VERSION ""

NS_ :

BS_:

BU_: AMS VCU

BO_ 3221225472 VECTOR__INDEPENDENT_SIG_MSG: 0 Vector__XXX
 SG_ NewSignal_0003 : 24|8@1+ (1,0) [0|0] "" Vector__XXX
 SG_ NewSignal_0008 : 40|8@1+ (1,0) [0|0] "" Vector__XXX

BO_ 131 Start_PreCharge: 1 VCU
 SG_ Precharge_Request : 0|1@0+ (1,0) [0|0] "ON/OFF" Vector__XXX

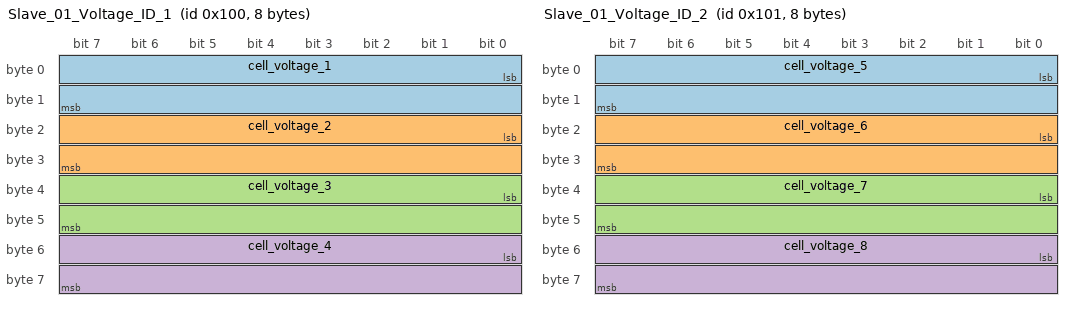
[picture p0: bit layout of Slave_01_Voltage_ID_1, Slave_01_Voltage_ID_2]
BO_ 256 Slave_01_Voltage_ID_1: 8 AMS
 SG_ cell_voltage_1 : 0|16@1+ (0.001,0) [0|0] "V" Vector__XXX
 SG_ cell_voltage_2 : 16|16@1+ (0.001,0) [0|0] "V" Vector__XXX
 SG_ cell_voltage_3 : 32|16@1+ (0.001,0) [0|0] "V" Vector__XXX
 SG_ cell_voltage_4 : 48|16@1+ (0.001,0) [0|0] "V" Vector__XXX

BO_ 257 Slave_01_Voltage_ID_2: 8 AMS
 SG_ cell_voltage_5 : 0|16@1+ (0.001,0) [0|0] "V" Vector__XXX
 SG_ cell_voltage_6 : 16|16@1+ (0.001,0) [0|0] "V" Vector__XXX
 SG_ cell_voltage_7 : 32|16@1+ (0.001,0) [0|0] "V" Vector__XXX
 SG_ cell_voltage_8 : 48|16@1+ (0.001,0) [0|0] "V" Vector__XXX

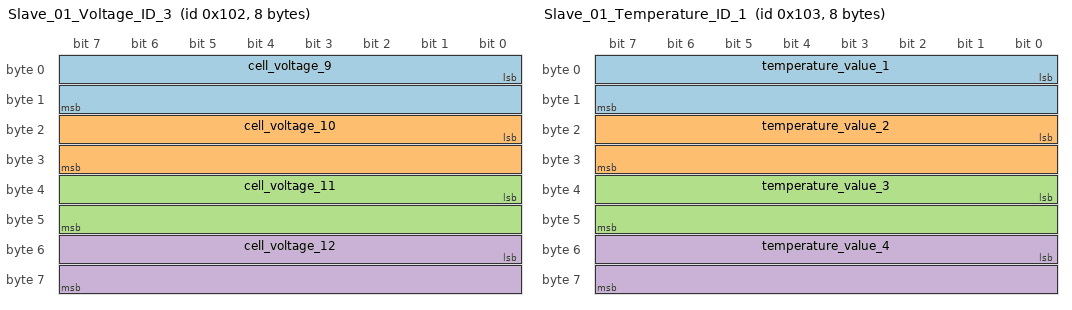
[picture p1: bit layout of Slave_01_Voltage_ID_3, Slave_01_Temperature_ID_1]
BO_ 258 Slave_01_Voltage_ID_3: 8 AMS
 SG_ cell_voltage_9 : 0|16@1+ (0.001,0) [0|0] "V" Vector__XXX
 SG_ cell_voltage_10 : 16|16@1+ (0.001,0) [0|0] "V" Vector__XXX
 SG_ cell_voltage_11 : 32|16@1+ (0.001,0) [0|0] "V" Vector__XXX
 SG_ cell_voltage_12 : 48|16@1+ (0.001,0) [0|0] "V" Vector__XXX

BO_ 259 Slave_01_Temperature_ID_1: 8 AMS
 SG_ temperature_value_1 : 0|16@1+ (0.01,0) [0|0] "ºC" Vector__XXX
 SG_ temperature_value_2 : 16|16@1+ (0.01,0) [0|0] "ºC" Vector__XXX
 SG_ temperature_value_3 : 32|16@1+ (0.01,0) [0|0] "ºC" Vector__XXX
 SG_ temperature_value_4 : 48|16@1+ (0.01,0) [0|0] "ºC" Vector__XXX

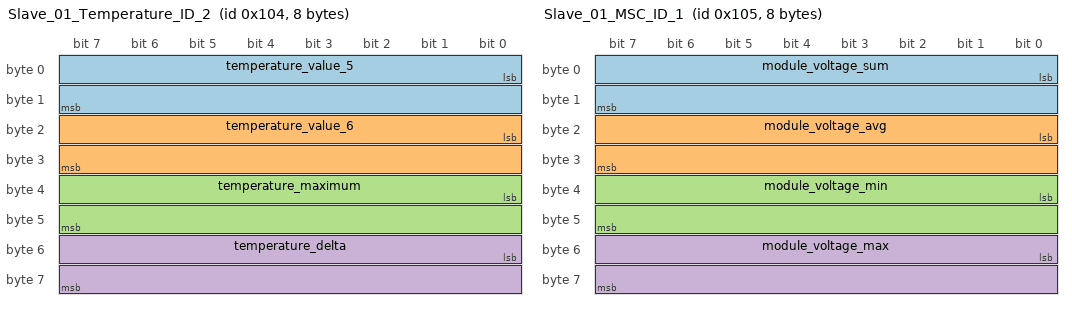
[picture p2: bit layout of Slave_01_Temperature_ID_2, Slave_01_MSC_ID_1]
BO_ 260 Slave_01_Temperature_ID_2: 8 AMS
 SG_ temperature_value_5 : 0|16@1+ (0.01,0) [0|0] "ºC" Vector__XXX
 SG_ temperature_value_6 : 16|16@1+ (0.01,0) [0|0] "ºC" Vector__XXX
 SG_ temperature_maximum : 32|16@1+ (0.01,0) [0|0] "ºC" Vector__XXX
 SG_ temperature_delta : 48|16@1+ (0.01,0) [0|0] "ºC" Vector__XXX

BO_ 261 Slave_01_MSC_ID_1: 8 AMS
 SG_ module_voltage_sum : 0|16@1+ (0.001,0) [0|0] "V" Vector__XXX
 SG_ module_voltage_avg : 16|16@1+ (0.001,0) [0|0] "V" Vector__XXX
 SG_ module_voltage_min : 32|16@1+ (0.001,0) [0|0] "V" Vector__XXX
 SG_ module_voltage_max : 48|16@1+ (0.001,0) [0|0] "V" Vector__XXX

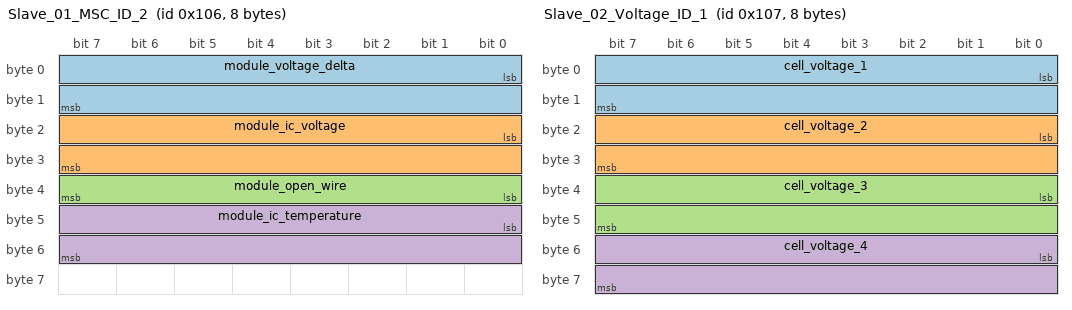
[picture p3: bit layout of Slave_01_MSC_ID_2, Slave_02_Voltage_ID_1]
BO_ 262 Slave_01_MSC_ID_2: 8 AMS
 SG_ module_voltage_delta : 0|16@1+ (0.001,0) [0|0] "V" Vector__XXX
 SG_ module_ic_voltage : 16|16@1+ (0.001,0) [0|0] "V" Vector__XXX
 SG_ module_open_wire : 32|8@1+ (1,0) [0|1] "" Vector__XXX
 SG_ module_ic_temperature : 40|16@1+ (1,0) [0|0] "ºC" Vector__XXX

BO_ 263 Slave_02_Voltage_ID_1: 8 AMS
 SG_ cell_voltage_1 : 0|16@1+ (0.001,0) [0|0] "V" Vector__XXX
 SG_ cell_voltage_2 : 16|16@1+ (0.001,0) [0|0] "V" Vector__XXX
 SG_ cell_voltage_3 : 32|16@1+ (0.001,0) [0|0] "V" Vector__XXX
 SG_ cell_voltage_4 : 48|16@1+ (0.001,0) [0|0] "V" Vector__XXX

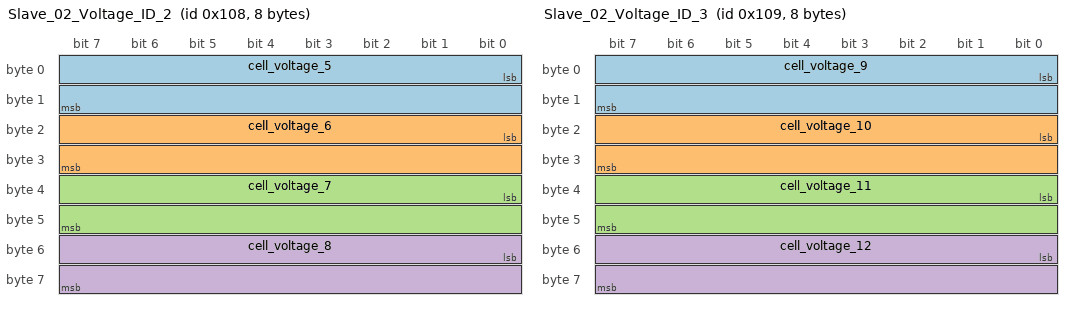
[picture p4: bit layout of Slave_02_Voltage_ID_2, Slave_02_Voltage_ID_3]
BO_ 264 Slave_02_Voltage_ID_2: 8 AMS
 SG_ cell_voltage_5 : 0|16@1+ (0.001,0) [0|0] "V" Vector__XXX
 SG_ cell_voltage_6 : 16|16@1+ (0.001,0) [0|0] "V" Vector__XXX
 SG_ cell_voltage_7 : 32|16@1+ (0.001,0) [0|0] "V" Vector__XXX
 SG_ cell_voltage_8 : 48|16@1+ (0.001,0) [0|0] "V" Vector__XXX

BO_ 265 Slave_02_Voltage_ID_3: 8 AMS
 SG_ cell_voltage_9 : 0|16@1+ (0.001,0) [0|0] "V" Vector__XXX
 SG_ cell_voltage_10 : 16|16@1+ (0.001,0) [0|0] "V" Vector__XXX
 SG_ cell_voltage_11 : 32|16@1+ (0.001,0) [0|0] "V" Vector__XXX
 SG_ cell_voltage_12 : 48|16@1+ (0.001,0) [0|0] "V" Vector__XXX

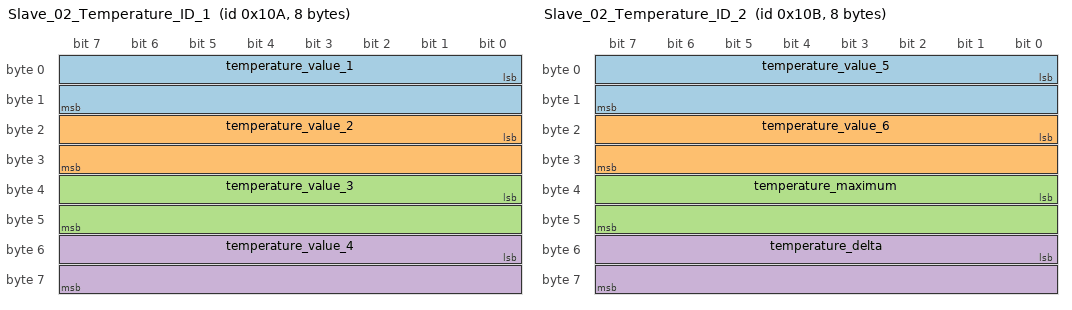
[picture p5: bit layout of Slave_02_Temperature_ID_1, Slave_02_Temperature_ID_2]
BO_ 266 Slave_02_Temperature_ID_1: 8 AMS
 SG_ temperature_value_1 : 0|16@1+ (0.01,0) [0|0] "ºC" Vector__XXX
 SG_ temperature_value_2 : 16|16@1+ (0.01,0) [0|0] "ºC" Vector__XXX
 SG_ temperature_value_3 : 32|16@1+ (0.01,0) [0|0] "ºC" Vector__XXX
 SG_ temperature_value_4 : 48|16@1+ (0.01,0) [0|0] "ºC" Vector__XXX

BO_ 267 Slave_02_Temperature_ID_2: 8 AMS
 SG_ temperature_value_5 : 0|16@1+ (0.01,0) [0|0] "ºC" Vector__XXX
 SG_ temperature_value_6 : 16|16@1+ (0.01,0) [0|0] "ºC" Vector__XXX
 SG_ temperature_maximum : 32|16@1+ (0.01,0) [0|0] "ºC" Vector__XXX
 SG_ temperature_delta : 48|16@1+ (0.01,0) [0|0] "ºC" Vector__XXX

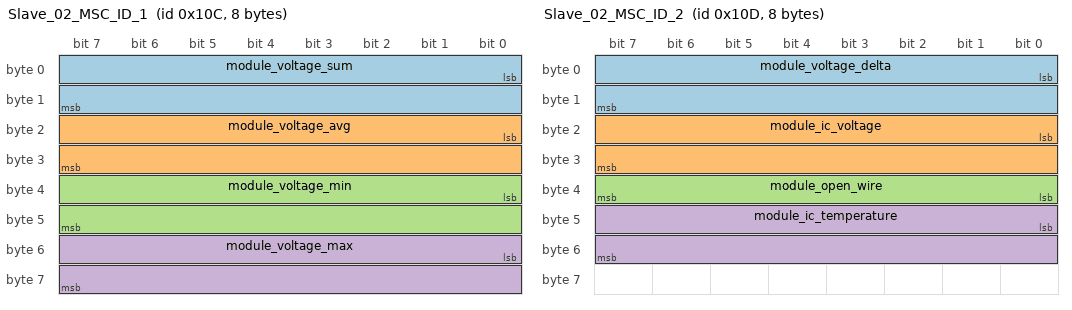
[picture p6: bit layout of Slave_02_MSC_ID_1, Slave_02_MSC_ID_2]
BO_ 268 Slave_02_MSC_ID_1: 8 AMS
 SG_ module_voltage_sum : 0|16@1+ (0.001,0) [0|0] "V" Vector__XXX
 SG_ module_voltage_avg : 16|16@1+ (0.001,0) [0|0] "V" Vector__XXX
 SG_ module_voltage_min : 32|16@1+ (0.001,0) [0|0] "V" Vector__XXX
 SG_ module_voltage_max : 48|16@1+ (0.001,0) [0|0] "V" Vector__XXX

BO_ 269 Slave_02_MSC_ID_2: 8 AMS
 SG_ module_voltage_delta : 0|16@1+ (0.001,0) [0|0] "V" Vector__XXX
 SG_ module_ic_voltage : 16|16@1+ (0.001,0) [0|0] "V" Vector__XXX
 SG_ module_open_wire : 32|8@1+ (1,0) [0|1] "" Vector__XXX
 SG_ module_ic_temperature : 40|16@1+ (1,0) [0|0] "ºC" Vector__XXX

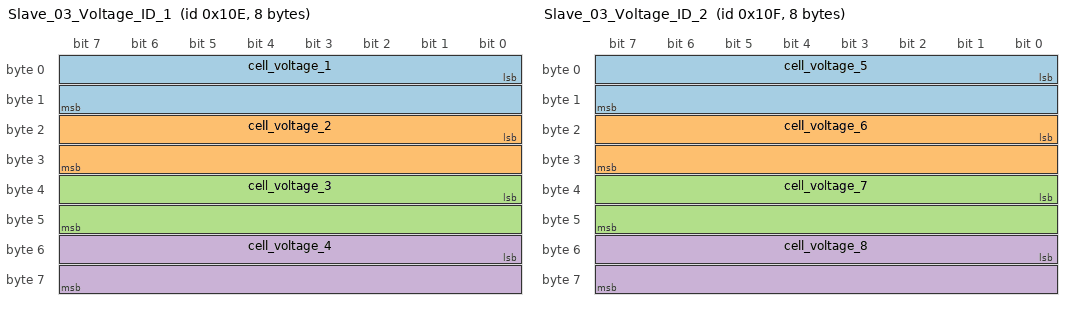
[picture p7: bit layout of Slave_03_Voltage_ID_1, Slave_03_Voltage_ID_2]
BO_ 270 Slave_03_Voltage_ID_1: 8 AMS
 SG_ cell_voltage_1 : 0|16@1+ (0.001,0) [0|0] "V" Vector__XXX
 SG_ cell_voltage_2 : 16|16@1+ (0.001,0) [0|0] "V" Vector__XXX
 SG_ cell_voltage_3 : 32|16@1+ (0.001,0) [0|0] "V" Vector__XXX
 SG_ cell_voltage_4 : 48|16@1+ (0.001,0) [0|0] "V" Vector__XXX

BO_ 271 Slave_03_Voltage_ID_2: 8 AMS
 SG_ cell_voltage_5 : 0|16@1+ (0.001,0) [0|0] "V" Vector__XXX
 SG_ cell_voltage_6 : 16|16@1+ (0.001,0) [0|0] "V" Vector__XXX
 SG_ cell_voltage_7 : 32|16@1+ (0.001,0) [0|0] "V" Vector__XXX
 SG_ cell_voltage_8 : 48|16@1+ (0.001,0) [0|0] "V" Vector__XXX

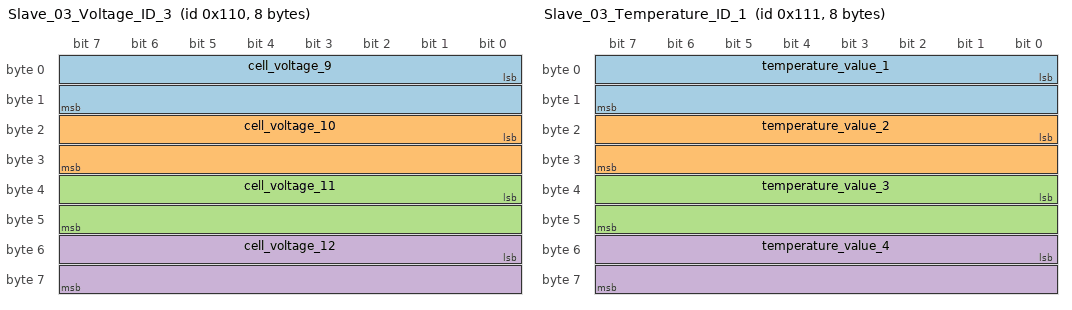
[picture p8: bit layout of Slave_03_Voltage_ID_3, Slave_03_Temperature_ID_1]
BO_ 272 Slave_03_Voltage_ID_3: 8 AMS
 SG_ cell_voltage_9 : 0|16@1+ (0.001,0) [0|0] "V" Vector__XXX
 SG_ cell_voltage_10 : 16|16@1+ (0.001,0) [0|0] "V" Vector__XXX
 SG_ cell_voltage_11 : 32|16@1+ (0.001,0) [0|0] "V" Vector__XXX
 SG_ cell_voltage_12 : 48|16@1+ (0.001,0) [0|0] "V" Vector__XXX

BO_ 273 Slave_03_Temperature_ID_1: 8 AMS
 SG_ temperature_value_1 : 0|16@1+ (0.01,0) [0|0] "ºC" Vector__XXX
 SG_ temperature_value_2 : 16|16@1+ (0.01,0) [0|0] "ºC" Vector__XXX
 SG_ temperature_value_3 : 32|16@1+ (0.01,0) [0|0] "ºC" Vector__XXX
 SG_ temperature_value_4 : 48|16@1+ (0.01,0) [0|0] "ºC" Vector__XXX

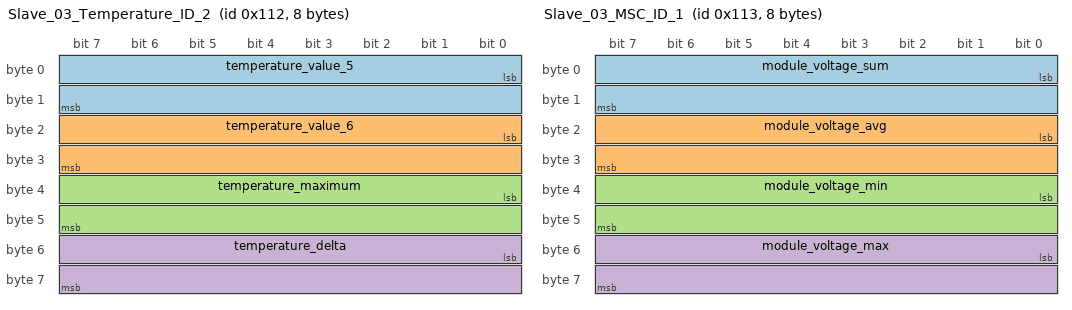
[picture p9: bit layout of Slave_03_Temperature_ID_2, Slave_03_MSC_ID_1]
BO_ 274 Slave_03_Temperature_ID_2: 8 AMS
 SG_ temperature_value_5 : 0|16@1+ (0.01,0) [0|0] "ºC" Vector__XXX
 SG_ temperature_value_6 : 16|16@1+ (0.01,0) [0|0] "ºC" Vector__XXX
 SG_ temperature_maximum : 32|16@1+ (0.01,0) [0|0] "ºC" Vector__XXX
 SG_ temperature_delta : 48|16@1+ (0.01,0) [0|0] "ºC" Vector__XXX

BO_ 275 Slave_03_MSC_ID_1: 8 AMS
 SG_ module_voltage_sum : 0|16@1+ (0.001,0) [0|0] "V" Vector__XXX
 SG_ module_voltage_avg : 16|16@1+ (0.001,0) [0|0] "V" Vector__XXX
 SG_ module_voltage_min : 32|16@1+ (0.001,0) [0|0] "V" Vector__XXX
 SG_ module_voltage_max : 48|16@1+ (0.001,0) [0|0] "V" Vector__XXX

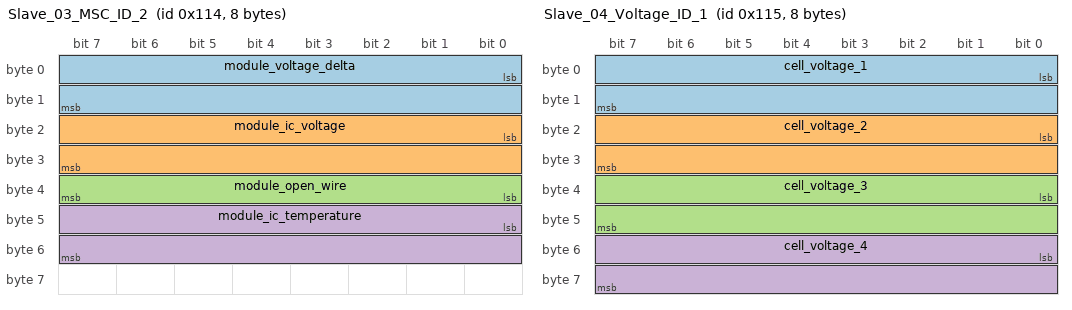
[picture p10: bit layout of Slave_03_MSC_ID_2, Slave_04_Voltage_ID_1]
BO_ 276 Slave_03_MSC_ID_2: 8 AMS
 SG_ module_voltage_delta : 0|16@1+ (0.001,0) [0|0] "V" Vector__XXX
 SG_ module_ic_voltage : 16|16@1+ (0.001,0) [0|0] "V" Vector__XXX
 SG_ module_open_wire : 32|8@1+ (1,0) [0|1] "" Vector__XXX
 SG_ module_ic_temperature : 40|16@1+ (1,0) [0|0] "ºC" Vector__XXX

BO_ 277 Slave_04_Voltage_ID_1: 8 AMS
 SG_ cell_voltage_1 : 0|16@1+ (0.001,0) [0|0] "V" Vector__XXX
 SG_ cell_voltage_2 : 16|16@1+ (0.001,0) [0|0] "V" Vector__XXX
 SG_ cell_voltage_3 : 32|16@1+ (0.001,0) [0|0] "V" Vector__XXX
 SG_ cell_voltage_4 : 48|16@1+ (0.001,0) [0|0] "V" Vector__XXX

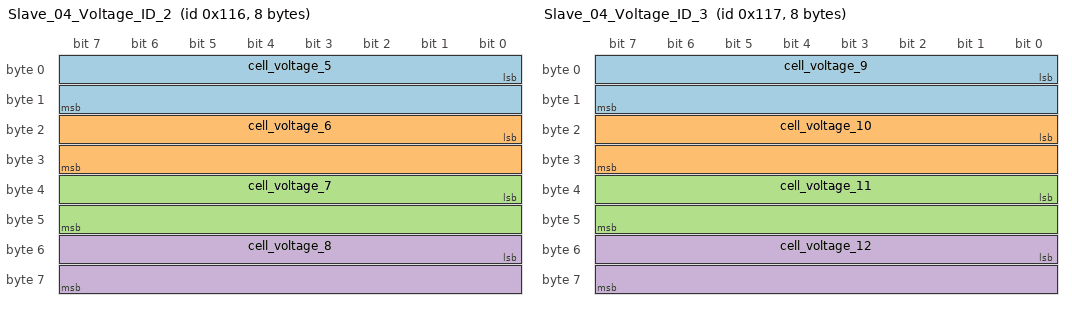
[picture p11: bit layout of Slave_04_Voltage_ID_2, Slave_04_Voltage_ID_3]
BO_ 278 Slave_04_Voltage_ID_2: 8 AMS
 SG_ cell_voltage_5 : 0|16@1+ (0.001,0) [0|0] "V" Vector__XXX
 SG_ cell_voltage_6 : 16|16@1+ (0.001,0) [0|0] "V" Vector__XXX
 SG_ cell_voltage_7 : 32|16@1+ (0.001,0) [0|0] "V" Vector__XXX
 SG_ cell_voltage_8 : 48|16@1+ (0.001,0) [0|0] "V" Vector__XXX

BO_ 279 Slave_04_Voltage_ID_3: 8 AMS
 SG_ cell_voltage_9 : 0|16@1+ (0.001,0) [0|0] "V" Vector__XXX
 SG_ cell_voltage_10 : 16|16@1+ (0.001,0) [0|0] "V" Vector__XXX
 SG_ cell_voltage_11 : 32|16@1+ (0.001,0) [0|0] "V" Vector__XXX
 SG_ cell_voltage_12 : 48|16@1+ (0.001,0) [0|0] "V" Vector__XXX

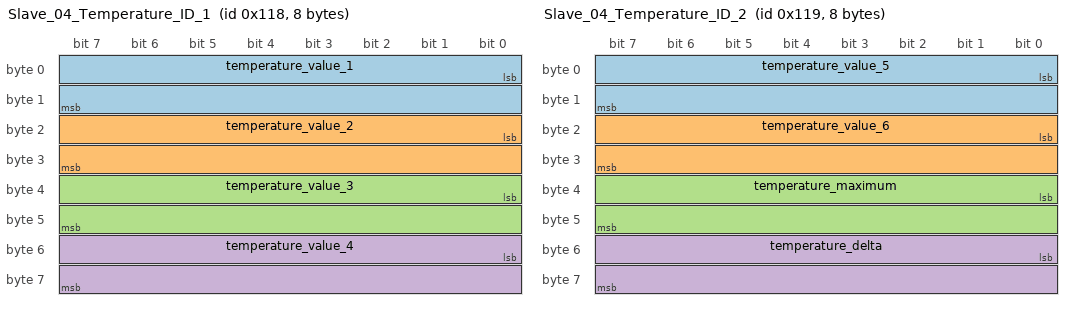
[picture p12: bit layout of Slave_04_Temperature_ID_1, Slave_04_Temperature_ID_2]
BO_ 280 Slave_04_Temperature_ID_1: 8 AMS
 SG_ temperature_value_1 : 0|16@1+ (0.01,0) [0|0] "ºC" Vector__XXX
 SG_ temperature_value_2 : 16|16@1+ (0.01,0) [0|0] "ºC" Vector__XXX
 SG_ temperature_value_3 : 32|16@1+ (0.01,0) [0|0] "ºC" Vector__XXX
 SG_ temperature_value_4 : 48|16@1+ (0.01,0) [0|0] "ºC" Vector__XXX

BO_ 281 Slave_04_Temperature_ID_2: 8 AMS
 SG_ temperature_value_5 : 0|16@1+ (0.01,0) [0|0] "ºC" Vector__XXX
 SG_ temperature_value_6 : 16|16@1+ (0.01,0) [0|0] "ºC" Vector__XXX
 SG_ temperature_maximum : 32|16@1+ (0.01,0) [0|0] "ºC" Vector__XXX
 SG_ temperature_delta : 48|16@1+ (0.01,0) [0|0] "ºC" Vector__XXX

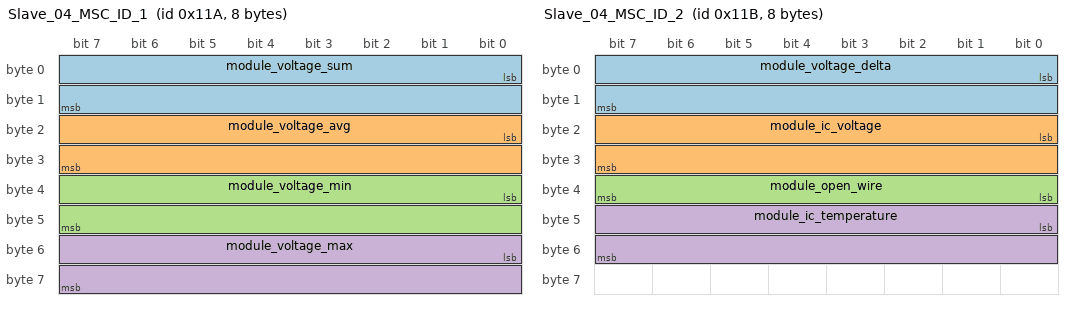
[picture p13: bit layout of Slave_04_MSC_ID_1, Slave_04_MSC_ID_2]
BO_ 282 Slave_04_MSC_ID_1: 8 AMS
 SG_ module_voltage_sum : 0|16@1+ (0.001,0) [0|0] "V" Vector__XXX
 SG_ module_voltage_avg : 16|16@1+ (0.001,0) [0|0] "V" Vector__XXX
 SG_ module_voltage_min : 32|16@1+ (0.001,0) [0|0] "V" Vector__XXX
 SG_ module_voltage_max : 48|16@1+ (0.001,0) [0|0] "V" Vector__XXX

BO_ 283 Slave_04_MSC_ID_2: 8 AMS
 SG_ module_voltage_delta : 0|16@1+ (0.001,0) [0|0] "V" Vector__XXX
 SG_ module_ic_voltage : 16|16@1+ (0.001,0) [0|0] "V" Vector__XXX
 SG_ module_open_wire : 32|8@1+ (1,0) [0|1] "" Vector__XXX
 SG_ module_ic_temperature : 40|16@1+ (1,0) [0|0] "ºC" Vector__XXX

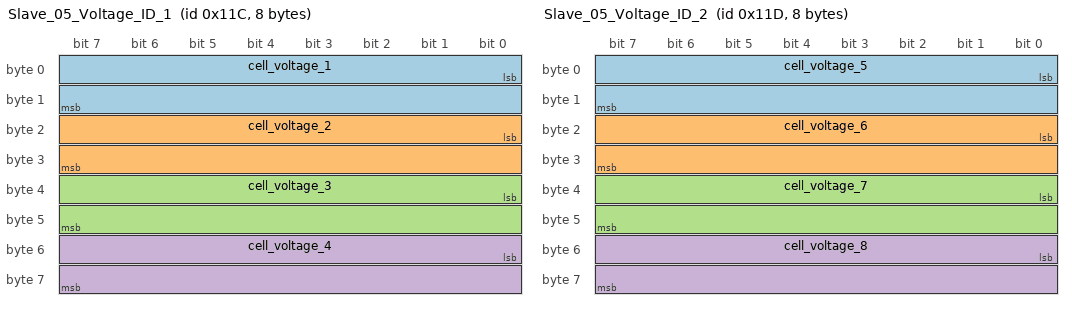
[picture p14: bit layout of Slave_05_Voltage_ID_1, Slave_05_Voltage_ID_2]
BO_ 284 Slave_05_Voltage_ID_1: 8 AMS
 SG_ cell_voltage_1 : 0|16@1+ (0.001,0) [0|0] "V" Vector__XXX
 SG_ cell_voltage_2 : 16|16@1+ (0.001,0) [0|0] "V" Vector__XXX
 SG_ cell_voltage_3 : 32|16@1+ (0.001,0) [0|0] "V" Vector__XXX
 SG_ cell_voltage_4 : 48|16@1+ (0.001,0) [0|0] "V" Vector__XXX

BO_ 285 Slave_05_Voltage_ID_2: 8 AMS
 SG_ cell_voltage_5 : 0|16@1+ (0.001,0) [0|0] "V" Vector__XXX
 SG_ cell_voltage_6 : 16|16@1+ (0.001,0) [0|0] "V" Vector__XXX
 SG_ cell_voltage_7 : 32|16@1+ (0.001,0) [0|0] "V" Vector__XXX
 SG_ cell_voltage_8 : 48|16@1+ (0.001,0) [0|0] "V" Vector__XXX

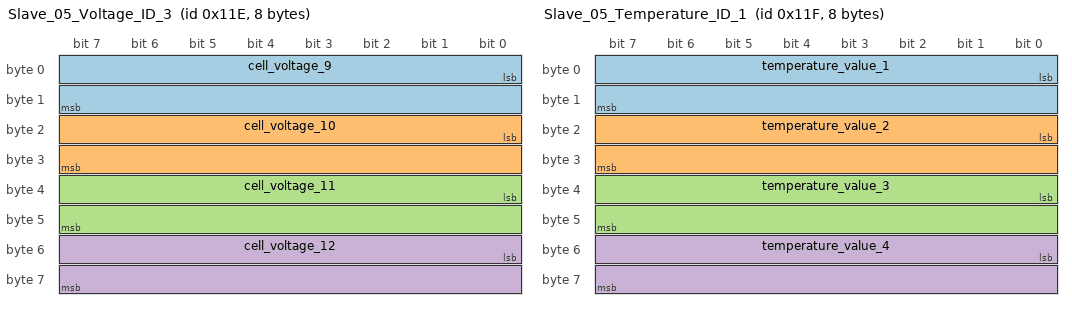
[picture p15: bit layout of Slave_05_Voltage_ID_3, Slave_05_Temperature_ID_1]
BO_ 286 Slave_05_Voltage_ID_3: 8 AMS
 SG_ cell_voltage_9 : 0|16@1+ (0.001,0) [0|0] "V" Vector__XXX
 SG_ cell_voltage_10 : 16|16@1+ (0.001,0) [0|0] "V" Vector__XXX
 SG_ cell_voltage_11 : 32|16@1+ (0.001,0) [0|0] "V" Vector__XXX
 SG_ cell_voltage_12 : 48|16@1+ (0.001,0) [0|0] "V" Vector__XXX

BO_ 287 Slave_05_Temperature_ID_1: 8 AMS
 SG_ temperature_value_1 : 0|16@1+ (0.01,0) [0|0] "ºC" Vector__XXX
 SG_ temperature_value_2 : 16|16@1+ (0.01,0) [0|0] "ºC" Vector__XXX
 SG_ temperature_value_3 : 32|16@1+ (0.01,0) [0|0] "ºC" Vector__XXX
 SG_ temperature_value_4 : 48|16@1+ (0.01,0) [0|0] "ºC" Vector__XXX

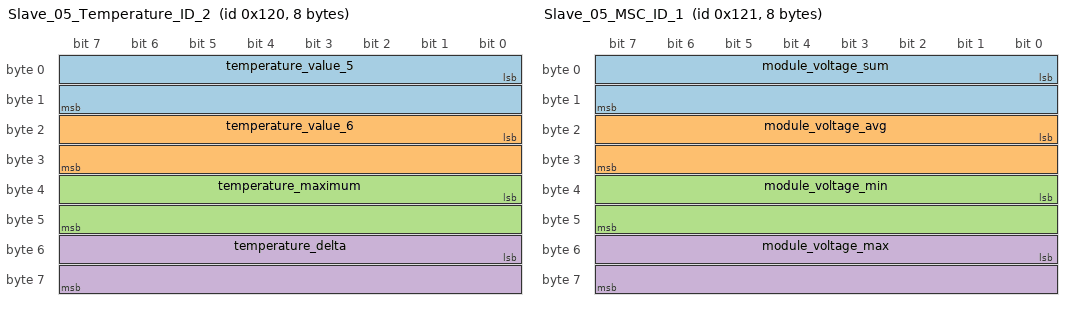
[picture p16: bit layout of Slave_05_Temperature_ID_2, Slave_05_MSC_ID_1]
BO_ 288 Slave_05_Temperature_ID_2: 8 AMS
 SG_ temperature_value_5 : 0|16@1+ (0.01,0) [0|0] "ºC" Vector__XXX
 SG_ temperature_value_6 : 16|16@1+ (0.01,0) [0|0] "ºC" Vector__XXX
 SG_ temperature_maximum : 32|16@1+ (0.01,0) [0|0] "ºC" Vector__XXX
 SG_ temperature_delta : 48|16@1+ (0.01,0) [0|0] "ºC" Vector__XXX

BO_ 289 Slave_05_MSC_ID_1: 8 AMS
 SG_ module_voltage_sum : 0|16@1+ (0.001,0) [0|0] "V" Vector__XXX
 SG_ module_voltage_avg : 16|16@1+ (0.001,0) [0|0] "V" Vector__XXX
 SG_ module_voltage_min : 32|16@1+ (0.001,0) [0|0] "V" Vector__XXX
 SG_ module_voltage_max : 48|16@1+ (0.001,0) [0|0] "V" Vector__XXX

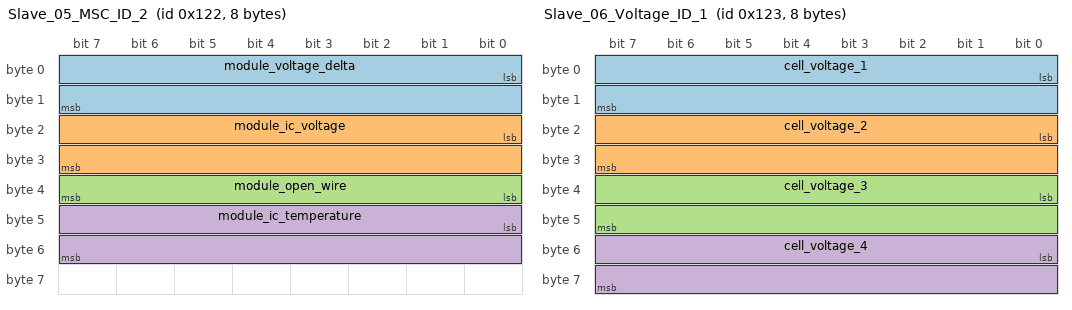
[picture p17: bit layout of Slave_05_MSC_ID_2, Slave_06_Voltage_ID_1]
BO_ 290 Slave_05_MSC_ID_2: 8 AMS
 SG_ module_voltage_delta : 0|16@1+ (0.001,0) [0|0] "V" Vector__XXX
 SG_ module_ic_voltage : 16|16@1+ (0.001,0) [0|0] "V" Vector__XXX
 SG_ module_open_wire : 32|8@1+ (1,0) [0|1] "" Vector__XXX
 SG_ module_ic_temperature : 40|16@1+ (1,0) [0|0] "ºC" Vector__XXX

BO_ 291 Slave_06_Voltage_ID_1: 8 AMS
 SG_ cell_voltage_1 : 0|16@1+ (0.001,0) [0|0] "V" Vector__XXX
 SG_ cell_voltage_2 : 16|16@1+ (0.001,0) [0|0] "V" Vector__XXX
 SG_ cell_voltage_3 : 32|16@1+ (0.001,0) [0|0] "V" Vector__XXX
 SG_ cell_voltage_4 : 48|16@1+ (0.001,0) [0|0] "V" Vector__XXX

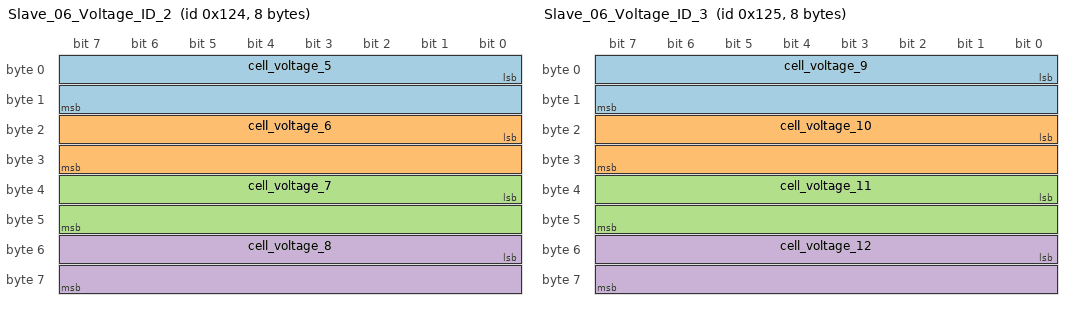
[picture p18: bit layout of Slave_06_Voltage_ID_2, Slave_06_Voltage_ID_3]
BO_ 292 Slave_06_Voltage_ID_2: 8 AMS
 SG_ cell_voltage_5 : 0|16@1+ (0.001,0) [0|0] "V" Vector__XXX
 SG_ cell_voltage_6 : 16|16@1+ (0.001,0) [0|0] "V" Vector__XXX
 SG_ cell_voltage_7 : 32|16@1+ (0.001,0) [0|0] "V" Vector__XXX
 SG_ cell_voltage_8 : 48|16@1+ (0.001,0) [0|0] "V" Vector__XXX

BO_ 293 Slave_06_Voltage_ID_3: 8 AMS
 SG_ cell_voltage_9 : 0|16@1+ (0.001,0) [0|0] "V" Vector__XXX
 SG_ cell_voltage_10 : 16|16@1+ (0.001,0) [0|0] "V" Vector__XXX
 SG_ cell_voltage_11 : 32|16@1+ (0.001,0) [0|0] "V" Vector__XXX
 SG_ cell_voltage_12 : 48|16@1+ (0.001,0) [0|0] "V" Vector__XXX

BO_ 294 Slave_06_Temperature_ID_1: 8 AMS
 SG_ temperature_value_1 : 0|16@1+ (0.01,0) [0|0] "ºC" Vector__XXX
 SG_ temperature_value_2 : 16|16@1+ (0.01,0) [0|0] "ºC" Vector__XXX
 SG_ temperature_value_3 : 32|16@1+ (0.01,0) [0|0] "ºC" Vector__XXX
 SG_ temperature_value_4 : 48|16@1+ (0.01,0) [0|0] "ºC" Vector__XXX

BO_ 295 Slave_06_Temperature_ID_2: 8 AMS
 SG_ temperature_value_5 : 0|16@1+ (0.01,0) [0|0] "ºC" Vector__XXX
 SG_ temperature_value_6 : 16|16@1+ (0.01,0) [0|0] "ºC" Vector__XXX
 SG_ temperature_maximum : 32|16@1+ (0.01,0) [0|0] "ºC" Vector__XXX
 SG_ temperature_delta : 48|16@1+ (0.01,0) [0|0] "ºC" Vector__XXX

BO_ 296 Slave_06_MSC_ID_1: 8 AMS
 SG_ module_voltage_sum : 0|16@1+ (0.001,0) [0|0] "V" Vector__XXX
 SG_ module_voltage_avg : 16|16@1+ (0.001,0) [0|0] "V" Vector__XXX
 SG_ module_voltage_min : 32|16@1+ (0.001,0) [0|0] "V" Vector__XXX
 SG_ module_voltage_max : 48|16@1+ (0.001,0) [0|0] "V" Vector__XXX

BO_ 297 Slave_06_MSC_ID_2: 8 AMS
 SG_ module_voltage_delta : 0|16@1+ (0.001,0) [0|0] "V" Vector__XXX
 SG_ module_ic_voltage : 16|16@1+ (0.001,0) [0|0] "V" Vector__XXX
 SG_ module_open_wire : 32|8@1+ (1,0) [0|1] "" Vector__XXX
 SG_ module_ic_temperature : 40|16@1+ (1,0) [0|0] "ºC" Vector__XXX

BO_ 298 Slave_07_Voltage_ID_1: 8 AMS
 SG_ cell_voltage_1 : 0|16@1+ (0.001,0) [0|0] "V" Vector__XXX
 SG_ cell_voltage_2 : 16|16@1+ (0.001,0) [0|0] "V" Vector__XXX
 SG_ cell_voltage_3 : 32|16@1+ (0.001,0) [0|0] "V" Vector__XXX
 SG_ cell_voltage_4 : 48|16@1+ (0.001,0) [0|0] "V" Vector__XXX

BO_ 299 Slave_07_Voltage_ID_2: 8 AMS
 SG_ cell_voltage_5 : 0|16@1+ (0.001,0) [0|0] "V" Vector__XXX
 SG_ cell_voltage_6 : 16|16@1+ (0.001,0) [0|0] "V" Vector__XXX
 SG_ cell_voltage_7 : 32|16@1+ (0.001,0) [0|0] "V" Vector__XXX
 SG_ cell_voltage_8 : 48|16@1+ (0.001,0) [0|0] "V" Vector__XXX

BO_ 300 Slave_07_Voltage_ID_3: 8 AMS
 SG_ cell_voltage_9 : 0|16@1+ (0.001,0) [0|0] "V" Vector__XXX
 SG_ cell_voltage_10 : 16|16@1+ (0.001,0) [0|0] "V" Vector__XXX
 SG_ cell_voltage_11 : 32|16@1+ (0.001,0) [0|0] "V" Vector__XXX
 SG_ cell_voltage_12 : 48|16@1+ (0.001,0) [0|0] "V" Vector__XXX

BO_ 301 Slave_07_Temperature_ID_1: 8 AMS
 SG_ temperature_value_1 : 0|16@1+ (0.01,0) [0|0] "ºC" Vector__XXX
 SG_ temperature_value_2 : 16|16@1+ (0.01,0) [0|0] "ºC" Vector__XXX
 SG_ temperature_value_3 : 32|16@1+ (0.01,0) [0|0] "ºC" Vector__XXX
 SG_ temperature_value_4 : 48|16@1+ (0.01,0) [0|0] "ºC" Vector__XXX

BO_ 302 Slave_07_Temperature_ID_2: 8 AMS
 SG_ temperature_value_5 : 0|16@1+ (0.01,0) [0|0] "ºC" Vector__XXX
 SG_ temperature_value_6 : 16|16@1+ (0.01,0) [0|0] "ºC" Vector__XXX
 SG_ temperature_maximum : 32|16@1+ (0.01,0) [0|0] "ºC" Vector__XXX
 SG_ temperature_delta : 48|16@1+ (0.01,0) [0|0] "ºC" Vector__XXX

BO_ 303 Slave_07_MSC_ID_1: 8 AMS
 SG_ module_voltage_sum : 0|16@1+ (0.001,0) [0|0] "V" Vector__XXX
 SG_ module_voltage_avg : 16|16@1+ (0.001,0) [0|0] "V" Vector__XXX
 SG_ module_voltage_min : 32|16@1+ (0.001,0) [0|0] "V" Vector__XXX
 SG_ module_voltage_max : 48|16@1+ (0.001,0) [0|0] "V" Vector__XXX

BO_ 304 Slave_07_MSC_ID_2: 8 AMS
 SG_ module_voltage_delta : 0|16@1+ (0.001,0) [0|0] "V" Vector__XXX
 SG_ module_ic_voltage : 16|16@1+ (0.001,0) [0|0] "V" Vector__XXX
 SG_ module_open_wire : 32|8@1+ (1,0) [0|1] "" Vector__XXX
 SG_ module_ic_temperature : 40|16@1+ (1,0) [0|0] "ºC" Vector__XXX

BO_ 305 Slave_08_Voltage_ID_1: 8 AMS
 SG_ cell_voltage_1 : 0|16@1+ (0.001,0) [0|0] "V" Vector__XXX
 SG_ cell_voltage_2 : 16|16@1+ (0.001,0) [0|0] "V" Vector__XXX
 SG_ cell_voltage_3 : 32|16@1+ (0.001,0) [0|0] "V" Vector__XXX
 SG_ cell_voltage_4 : 48|16@1+ (0.001,0) [0|0] "V" Vector__XXX

BO_ 306 Slave_08_Voltage_ID_2: 8 AMS
 SG_ cell_voltage_5 : 0|16@1+ (0.001,0) [0|0] "V" Vector__XXX
 SG_ cell_voltage_6 : 16|16@1+ (0.001,0) [0|0] "V" Vector__XXX
 SG_ cell_voltage_7 : 32|16@1+ (0.001,0) [0|0] "V" Vector__XXX
 SG_ cell_voltage_8 : 48|16@1+ (0.001,0) [0|0] "V" Vector__XXX

BO_ 307 Slave_08_Voltage_ID_3: 8 AMS
 SG_ cell_voltage_9 : 0|16@1+ (0.001,0) [0|0] "V" Vector__XXX
 SG_ cell_voltage_10 : 16|16@1+ (0.001,0) [0|0] "V" Vector__XXX
 SG_ cell_voltage_11 : 32|16@1+ (0.001,0) [0|0] "V" Vector__XXX
 SG_ cell_voltage_12 : 48|16@1+ (0.001,0) [0|0] "V" Vector__XXX

BO_ 308 Slave_08_Temperature_ID_1: 8 AMS
 SG_ temperature_value_1 : 0|16@1+ (0.01,0) [0|0] "ºC" Vector__XXX
 SG_ temperature_value_2 : 16|16@1+ (0.01,0) [0|0] "ºC" Vector__XXX
 SG_ temperature_value_3 : 32|16@1+ (0.01,0) [0|0] "ºC" Vector__XXX
 SG_ temperature_value_4 : 48|16@1+ (0.01,0) [0|0] "ºC" Vector__XXX

BO_ 309 Slave_08_Temperature_ID_2: 8 AMS
 SG_ temperature_value_5 : 0|16@1+ (0.01,0) [0|0] "ºC" Vector__XXX
 SG_ temperature_value_6 : 16|16@1+ (0.01,0) [0|0] "ºC" Vector__XXX
 SG_ temperature_maximum : 32|16@1+ (0.01,0) [0|0] "ºC" Vector__XXX
 SG_ temperature_delta : 48|16@1+ (0.01,0) [0|0] "ºC" Vector__XXX

BO_ 310 Slave_08_MSC_ID_1: 8 AMS
 SG_ module_voltage_sum : 0|16@1+ (0.001,0) [0|0] "V" Vector__XXX
 SG_ module_voltage_avg : 16|16@1+ (0.001,0) [0|0] "V" Vector__XXX
 SG_ module_voltage_min : 32|16@1+ (0.001,0) [0|0] "V" Vector__XXX
 SG_ module_voltage_max : 48|16@1+ (0.001,0) [0|0] "V" Vector__XXX

BO_ 311 Slave_08_MSC_ID_2: 8 AMS
 SG_ module_voltage_delta : 0|16@1+ (0.001,0) [0|0] "V" Vector__XXX
 SG_ module_ic_voltage : 16|16@1+ (0.001,0) [0|0] "V" Vector__XXX
 SG_ module_open_wire : 32|8@1+ (1,0) [0|1] "" Vector__XXX
 SG_ module_ic_temperature : 40|16@1+ (1,0) [0|0] "ºC" Vector__XXX

BO_ 312 Slave_09_Voltage_ID_1: 8 AMS
 SG_ cell_voltage_1 : 0|16@1+ (0.001,0) [0|0] "V" Vector__XXX
 SG_ cell_voltage_2 : 16|16@1+ (0.001,0) [0|0] "V" Vector__XXX
 SG_ cell_voltage_3 : 32|16@1+ (0.001,0) [0|0] "V" Vector__XXX
 SG_ cell_voltage_4 : 48|16@1+ (0.001,0) [0|0] "V" Vector__XXX

BO_ 313 Slave_09_Voltage_ID_2: 8 AMS
 SG_ cell_voltage_5 : 0|16@1+ (0.001,0) [0|0] "V" Vector__XXX
 SG_ cell_voltage_6 : 16|16@1+ (0.001,0) [0|0] "V" Vector__XXX
 SG_ cell_voltage_7 : 32|16@1+ (0.001,0) [0|0] "V" Vector__XXX
 SG_ cell_voltage_8 : 48|16@1+ (0.001,0) [0|0] "V" Vector__XXX

BO_ 314 Slave_09_Voltage_ID_3: 8 AMS
 SG_ cell_voltage_9 : 0|16@1+ (0.001,0) [0|0] "V" Vector__XXX
 SG_ cell_voltage_10 : 16|16@1+ (0.001,0) [0|0] "V" Vector__XXX
 SG_ cell_voltage_11 : 32|16@1+ (0.001,0) [0|0] "V" Vector__XXX
 SG_ cell_voltage_12 : 48|16@1+ (0.001,0) [0|0] "V" Vector__XXX

BO_ 315 Slave_09_Temperature_ID_1: 8 AMS
 SG_ temperature_value_1 : 0|16@1+ (0.01,0) [0|0] "ºC" Vector__XXX
 SG_ temperature_value_2 : 16|16@1+ (0.01,0) [0|0] "ºC" Vector__XXX
 SG_ temperature_value_3 : 32|16@1+ (0.01,0) [0|0] "ºC" Vector__XXX
 SG_ temperature_value_4 : 48|16@1+ (0.01,0) [0|0] "ºC" Vector__XXX

BO_ 316 Slave_09_Temperature_ID_2: 8 AMS
 SG_ temperature_value_5 : 0|16@1+ (0.01,0) [0|0] "ºC" Vector__XXX
 SG_ temperature_value_6 : 16|16@1+ (0.01,0) [0|0] "ºC" Vector__XXX
 SG_ temperature_maximum : 32|16@1+ (0.01,0) [0|0] "ºC" Vector__XXX
 SG_ temperature_delta : 48|16@1+ (0.01,0) [0|0] "ºC" Vector__XXX

BO_ 317 Slave_09_MSC_ID_1: 8 AMS
 SG_ module_voltage_sum : 0|16@1+ (0.001,0) [0|0] "V" Vector__XXX
 SG_ module_voltage_avg : 16|16@1+ (0.001,0) [0|0] "V" Vector__XXX
 SG_ module_voltage_min : 32|16@1+ (0.001,0) [0|0] "V" Vector__XXX
 SG_ module_voltage_max : 48|16@1+ (0.001,0) [0|0] "V" Vector__XXX

BO_ 318 Slave_09_MSC_ID_2: 8 AMS
 SG_ module_voltage_delta : 0|16@1+ (0.001,0) [0|0] "V" Vector__XXX
 SG_ module_ic_voltage : 16|16@1+ (0.001,0) [0|0] "V" Vector__XXX
 SG_ module_open_wire : 32|8@1+ (1,0) [0|1] "" Vector__XXX
 SG_ module_ic_temperature : 40|16@1+ (1,0) [0|0] "ºC" Vector__XXX

BO_ 319 Slave_10_Voltage_ID_1: 8 AMS
 SG_ cell_voltage_1 : 0|16@1+ (0.001,0) [0|0] "V" Vector__XXX
 SG_ cell_voltage_2 : 16|16@1+ (0.001,0) [0|0] "V" Vector__XXX
 SG_ cell_voltage_3 : 32|16@1+ (0.001,0) [0|0] "V" Vector__XXX
 SG_ cell_voltage_4 : 48|16@1+ (0.001,0) [0|0] "V" Vector__XXX

BO_ 320 Slave_10_Voltage_ID_2: 8 AMS
 SG_ cell_voltage_5 : 0|16@1+ (0.001,0) [0|0] "V" Vector__XXX
 SG_ cell_voltage_6 : 16|16@1+ (0.001,0) [0|0] "V" Vector__XXX
 SG_ cell_voltage_7 : 32|16@1+ (0.001,0) [0|0] "V" Vector__XXX
 SG_ cell_voltage_8 : 48|16@1+ (0.001,0) [0|0] "V" Vector__XXX

BO_ 321 Slave_10_Voltage_ID_3: 8 AMS
 SG_ cell_voltage_9 : 0|16@1+ (0.001,0) [0|0] "V" Vector__XXX
 SG_ cell_voltage_10 : 16|16@1+ (0.001,0) [0|0] "V" Vector__XXX
 SG_ cell_voltage_11 : 32|16@1+ (0.001,0) [0|0] "V" Vector__XXX
 SG_ cell_voltage_12 : 48|16@1+ (0.001,0) [0|0] "V" Vector__XXX

BO_ 322 Slave_10_Temperature_ID_1: 8 AMS
 SG_ temperature_value_1 : 0|16@1+ (0.01,0) [0|0] "ºC" Vector__XXX
 SG_ temperature_value_2 : 16|16@1+ (0.01,0) [0|0] "ºC" Vector__XXX
 SG_ temperature_value_3 : 32|16@1+ (0.01,0) [0|0] "ºC" Vector__XXX
 SG_ temperature_value_4 : 48|16@1+ (0.01,0) [0|0] "ºC" Vector__XXX

BO_ 323 Slave_10_Temperature_ID_2: 8 AMS
 SG_ temperature_value_5 : 0|16@1+ (0.01,0) [0|0] "ºC" Vector__XXX
 SG_ temperature_value_6 : 16|16@1+ (0.01,0) [0|0] "ºC" Vector__XXX
 SG_ temperature_maximum : 32|16@1+ (0.01,0) [0|0] "ºC" Vector__XXX
 SG_ temperature_delta : 48|16@1+ (0.01,0) [0|0] "ºC" Vector__XXX

BO_ 324 Slave_10_MSC_ID_1: 8 AMS
 SG_ module_voltage_sum : 0|16@1+ (0.001,0) [0|0] "V" Vector__XXX
 SG_ module_voltage_avg : 16|16@1+ (0.001,0) [0|0] "V" Vector__XXX
 SG_ module_voltage_min : 32|16@1+ (0.001,0) [0|0] "V" Vector__XXX
 SG_ module_voltage_max : 48|16@1+ (0.001,0) [0|0] "V" Vector__XXX

BO_ 325 Slave_10_MSC_ID_2: 8 AMS
 SG_ module_voltage_delta : 0|16@1+ (0.001,0) [0|0] "V" Vector__XXX
 SG_ module_ic_voltage : 16|16@1+ (0.001,0) [0|0] "V" Vector__XXX
 SG_ module_open_wire : 32|8@1+ (1,0) [0|1] "" Vector__XXX
 SG_ module_ic_temperature : 40|16@1+ (1,0) [0|0] "ºC" Vector__XXX

BO_ 326 Slave_11_Voltage_ID_1: 8 AMS
 SG_ cell_voltage_1 : 0|16@1+ (0.001,0) [0|0] "V" Vector__XXX
 SG_ cell_voltage_2 : 16|16@1+ (0.001,0) [0|0] "V" Vector__XXX
 SG_ cell_voltage_3 : 32|16@1+ (0.001,0) [0|0] "V" Vector__XXX
 SG_ cell_voltage_4 : 48|16@1+ (0.001,0) [0|0] "V" Vector__XXX

BO_ 327 Slave_11_Voltage_ID_2: 8 AMS
 SG_ cell_voltage_5 : 0|16@1+ (0.001,0) [0|0] "V" Vector__XXX
 SG_ cell_voltage_6 : 16|16@1+ (0.001,0) [0|0] "V" Vector__XXX
 SG_ cell_voltage_7 : 32|16@1+ (0.001,0) [0|0] "V" Vector__XXX
 SG_ cell_voltage_8 : 48|16@1+ (0.001,0) [0|0] "V" Vector__XXX

BO_ 328 Slave_11_Voltage_ID_3: 8 AMS
 SG_ cell_voltage_9 : 0|16@1+ (0.001,0) [0|0] "V" Vector__XXX
 SG_ cell_voltage_10 : 16|16@1+ (0.001,0) [0|0] "V" Vector__XXX
 SG_ cell_voltage_11 : 32|16@1+ (0.001,0) [0|0] "V" Vector__XXX
 SG_ cell_voltage_12 : 48|16@1+ (0.001,0) [0|0] "V" Vector__XXX

BO_ 329 Slave_11_Temperature_ID_1: 8 AMS
 SG_ temperature_value_1 : 0|16@1+ (0.01,0) [0|0] "ºC" Vector__XXX
 SG_ temperature_value_2 : 16|16@1+ (0.01,0) [0|0] "ºC" Vector__XXX
 SG_ temperature_value_3 : 32|16@1+ (0.01,0) [0|0] "ºC" Vector__XXX
 SG_ temperature_value_4 : 48|16@1+ (0.01,0) [0|0] "ºC" Vector__XXX

BO_ 330 Slave_11_Temperature_ID_2: 8 AMS
 SG_ temperature_value_5 : 0|16@1+ (0.01,0) [0|0] "ºC" Vector__XXX
 SG_ temperature_value_6 : 16|16@1+ (0.01,0) [0|0] "ºC" Vector__XXX
 SG_ temperature_maximum : 32|16@1+ (0.01,0) [0|0] "ºC" Vector__XXX
 SG_ temperature_delta : 48|16@1+ (0.01,0) [0|0] "ºC" Vector__XXX

BO_ 331 Slave_11_MSC_ID_1: 8 AMS
 SG_ module_voltage_sum : 0|16@1+ (0.001,0) [0|0] "V" Vector__XXX
 SG_ module_voltage_avg : 16|16@1+ (0.001,0) [0|0] "V" Vector__XXX
 SG_ module_voltage_min : 32|16@1+ (0.001,0) [0|0] "V" Vector__XXX
 SG_ module_voltage_max : 48|16@1+ (0.001,0) [0|0] "V" Vector__XXX

BO_ 332 Slave_11_MSC_ID_2: 8 AMS
 SG_ module_voltage_delta : 0|16@1+ (0.001,0) [0|0] "V" Vector__XXX
 SG_ module_ic_voltage : 16|16@1+ (0.001,0) [0|0] "V" Vector__XXX
 SG_ module_open_wire : 32|8@1+ (1,0) [0|1] "" Vector__XXX
 SG_ module_ic_temperature : 40|16@1+ (1,0) [0|0] "ºC" Vector__XXX

BO_ 333 Slave_12_Voltage_ID_1: 8 AMS
 SG_ cell_voltage_1 : 0|16@1+ (0.001,0) [0|0] "V" Vector__XXX
 SG_ cell_voltage_2 : 16|16@1+ (0.001,0) [0|0] "V" Vector__XXX
 SG_ cell_voltage_3 : 32|16@1+ (0.001,0) [0|0] "V" Vector__XXX
 SG_ cell_voltage_4 : 48|16@1+ (0.001,0) [0|0] "V" Vector__XXX

BO_ 334 Slave_12_Voltage_ID_2: 8 AMS
 SG_ cell_voltage_5 : 0|16@1+ (0.001,0) [0|0] "V" Vector__XXX
 SG_ cell_voltage_6 : 16|16@1+ (0.001,0) [0|0] "V" Vector__XXX
 SG_ cell_voltage_7 : 32|16@1+ (0.001,0) [0|0] "V" Vector__XXX
 SG_ cell_voltage_8 : 48|16@1+ (0.001,0) [0|0] "V" Vector__XXX

BO_ 335 Slave_12_Voltage_ID_3: 8 AMS
 SG_ cell_voltage_9 : 0|16@1+ (0.001,0) [0|0] "V" Vector__XXX
 SG_ cell_voltage_10 : 16|16@1+ (0.001,0) [0|0] "V" Vector__XXX
 SG_ cell_voltage_11 : 32|16@1+ (0.001,0) [0|0] "V" Vector__XXX
 SG_ cell_voltage_12 : 48|16@1+ (0.001,0) [0|0] "V" Vector__XXX

BO_ 336 Slave_12_Temperature_ID_1: 8 AMS
 SG_ temperature_value_1 : 0|16@1+ (0.01,0) [0|0] "ºC" Vector__XXX
 SG_ temperature_value_2 : 16|16@1+ (0.01,0) [0|0] "ºC" Vector__XXX
 SG_ temperature_value_3 : 32|16@1+ (0.01,0) [0|0] "ºC" Vector__XXX
 SG_ temperature_value_4 : 48|16@1+ (0.01,0) [0|0] "ºC" Vector__XXX

BO_ 337 Slave_12_Temperature_ID_2: 8 AMS
 SG_ temperature_value_5 : 0|16@1+ (0.01,0) [0|0] "ºC" Vector__XXX
 SG_ temperature_value_6 : 16|16@1+ (0.01,0) [0|0] "ºC" Vector__XXX
 SG_ temperature_maximum : 32|16@1+ (0.01,0) [0|0] "ºC" Vector__XXX
 SG_ temperature_delta : 48|16@1+ (0.01,0) [0|0] "ºC" Vector__XXX

BO_ 338 Slave_12_MSC_ID_1: 8 AMS
 SG_ module_voltage_sum : 0|16@1+ (0.001,0) [0|0] "V" Vector__XXX
 SG_ module_voltage_avg : 16|16@1+ (0.001,0) [0|0] "V" Vector__XXX
 SG_ module_voltage_min : 32|16@1+ (0.001,0) [0|0] "V" Vector__XXX
 SG_ module_voltage_max : 48|16@1+ (0.001,0) [0|0] "V" Vector__XXX

BO_ 339 Slave_12_MSC_ID_2: 8 AMS
 SG_ module_voltage_delta : 0|16@1+ (0.001,0) [0|0] "V" Vector__XXX
 SG_ module_ic_voltage : 16|16@1+ (0.001,0) [0|0] "V" Vector__XXX
 SG_ module_open_wire : 32|8@1+ (1,0) [0|1] "" Vector__XXX
 SG_ module_ic_temperature : 40|16@1+ (1,0) [0|0] "ºC" Vector__XXX

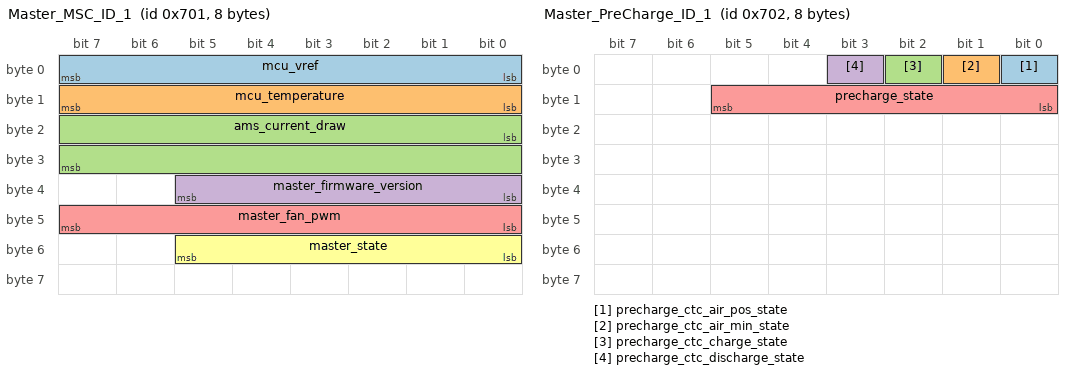
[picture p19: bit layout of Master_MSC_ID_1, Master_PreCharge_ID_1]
BO_ 1793 Master_MSC_ID_1: 8 AMS
 SG_ mcu_vref : 0|8@1+ (0.01,2) [0|0] "V" Vector__XXX
 SG_ mcu_temperature : 8|8@1+ (1,0) [0|0] "ºC" Vector__XXX
 SG_ ams_current_draw : 16|16@1+ (0.001,0) [0|65535] "A" Vector__XXX
 SG_ master_firmware_version : 32|6@1+ (1,0) [0|0] "" Vector__XXX
 SG_ master_fan_pwm : 40|8@1+ (0.392,0) [0|100] "PWM" Vector__XXX
 SG_ master_state : 48|6@1+ (1,0) [0|0] "" Vector__XXX

BO_ 1794 Master_PreCharge_ID_1: 8 AMS
 SG_ precharge_ctc_air_pos_state : 0|1@1+ (1,0) [0|0] "ON/OFF" Vector__XXX
 SG_ precharge_ctc_air_min_state : 1|1@1+ (1,0) [0|0] "ON/OFF" Vector__XXX
 SG_ precharge_ctc_charge_state : 2|1@1+ (1,0) [0|0] "ON/OFF" Vector__XXX
 SG_ precharge_ctc_discharge_state : 3|1@1+ (1,0) [0|0] "ON/OFF" Vector__XXX
 SG_ precharge_state : 8|6@1+ (1,0) [0|0] "" Vector__XXX

CM_ SG_ 1793 master_state "Master State Machine
";
CM_ SG_ 1794 precharge_state "Pecharge State Machine";
BA_DEF_  "BusType" STRING ;
BA_DEF_DEF_  "BusType" "CAN";
VAL_ 262 module_open_wire 0 "No fault detected" 1 "Cell/open-wire/voltage diagnostic fault" ;
VAL_ 269 module_open_wire 0 "No fault detected" 1 "Cell/open-wire/voltage diagnostic fault" ;
VAL_ 276 module_open_wire 0 "No fault detected" 1 "Cell/open-wire/voltage diagnostic fault" ;
VAL_ 283 module_open_wire 0 "No fault detected" 1 "Cell/open-wire/voltage diagnostic fault" ;
VAL_ 290 module_open_wire 0 "No fault detected" 1 "Cell/open-wire/voltage diagnostic fault" ;
VAL_ 297 module_open_wire 0 "No fault detected" 1 "Cell/open-wire/voltage diagnostic fault" ;
VAL_ 304 module_open_wire 0 "No fault detected" 1 "Cell/open-wire/voltage diagnostic fault" ;
VAL_ 311 module_open_wire 0 "No fault detected" 1 "Cell/open-wire/voltage diagnostic fault" ;
VAL_ 318 module_open_wire 0 "No fault detected" 1 "Cell/open-wire/voltage diagnostic fault" ;
VAL_ 325 module_open_wire 0 "No fault detected" 1 "Cell/open-wire/voltage diagnostic fault" ;
VAL_ 332 module_open_wire 0 "No fault detected" 1 "Cell/open-wire/voltage diagnostic fault" ;
VAL_ 339 module_open_wire 0 "No fault detected" 1 "Cell/open-wire/voltage diagnostic fault" ;
VAL_ 1793 master_firmware_version 0 "Unknown Firmware" 1 "alpha" 3 "beta" 5 "alpha-v1" 7 "beta-v1" 9 "alpha-v2" 13 "alpha-v3" 17 "alpha-v3.1" 11 "beta-v2" 15 "beta-v3" ;
VAL_ 1793 master_state 0 "BALANCING" 1 "CHARGING" 2 "IDLE" 3 "ONMISSION" 4 "STARTUP" 5 "DISCHARGE_TEST" 6 "RESET_ISA" 7 "FAULT" ;
VAL_ 1794 precharge_state 0 "START" 1 "OPEN_ALL" 2 "SWITCH_HVNEG" 3 "DELAY1" 4 "VERIFY1" 5 "SWITCH_PRECHARGE" 6 "DELAY2" 7 "VERIFY2" 8 "VERIFY_CURRENT" 9 "VERIFY_BUS_VOLT" 10 "SWITCH_HVPOS" 11 "DELAY3" 12 "VERIFY3" 13 "TURN_OFF_PRECHARGE" 14 "DELAY4" 15 "VERIFY4" 16 "END" 17 "WRONG" 18 "KILL" 19 "RX_CAN" ;
